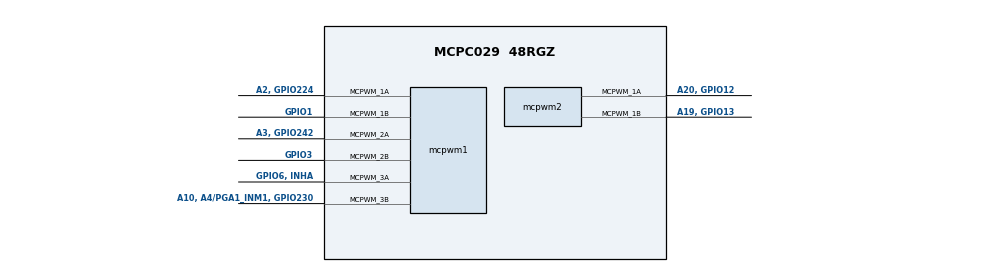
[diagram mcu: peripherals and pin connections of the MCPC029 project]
/**
 * @cliArgs --device "MCPC029" --part "MCPC029_48RGZ" --package "48RGZ"
 */
/**
 * Import the modules used in this configuration.
 */
const mcpwm  = scripting.addModule("/driverlib/mcpwm.js");
const mcpwm1 = mcpwm.addInstance();
const mcpwm2 = mcpwm.addInstance();
/**
 * Write custom configuration values to the imported modules.
 */
mcpwm.commentOutDefaultCode = true;
mcpwm1.$name                                                       = "myMCPWM0";
mcpwm1.mcpwmTimebase_counterMode                                   = "MCPWM_COUNTER_MODE_UP";
mcpwm1.mcpwmTimebase_period                                        = 15999;
mcpwm1.mcpwmCounterCompare_cmpA                                    = 7999;
mcpwm1.mcpwmTimebase_emulationMode                                 = "MCPWM_EMULATION_FREE_RUN";
mcpwm1.mcpwmCounterCompare_cmpB                                    = 7999;
mcpwm1.mcpwmActionQualifier_MCPWM_AQ_OUTPUT_1A_ON_TIMEBASE_ZERO    = "MCPWM_AQ_OUTPUT_HIGH";
mcpwm1.mcpwmActionQualifier_MCPWM_AQ_OUTPUT_1B_ON_TIMEBASE_ZERO    = "MCPWM_AQ_OUTPUT_HIGH";
mcpwm1.mcpwmActionQualifier_MCPWM_AQ_OUTPUT_1A_ON_TIMEBASE_UP_CMPA = "MCPWM_AQ_OUTPUT_LOW";
mcpwm1.mcpwmActionQualifier_MCPWM_AQ_OUTPUT_1B_ON_TIMEBASE_UP_CMPB = "MCPWM_AQ_OUTPUT_LOW";
mcpwm1.mcpwmActionQualifier_MCPWM_AQ_OUTPUT_2A_ON_TIMEBASE_PERIOD  = "MCPWM_AQ_OUTPUT_LOW";
mcpwm1.mcpwmActionQualifier_MCPWM_AQ_OUTPUT_2B_ON_TIMEBASE_PERIOD  = "MCPWM_AQ_OUTPUT_LOW";
mcpwm1.mcpwmActionQualifier_MCPWM_AQ_OUTPUT_2A_ON_TIMEBASE_UP_CMPA = "MCPWM_AQ_OUTPUT_HIGH";
mcpwm1.mcpwmActionQualifier_MCPWM_AQ_OUTPUT_2B_ON_TIMEBASE_UP_CMPB = "MCPWM_AQ_OUTPUT_HIGH";
mcpwm1.mcpwmActionQualifier_MCPWM_AQ_OUTPUT_3A_ON_TIMEBASE_UP_CMPA = "MCPWM_AQ_OUTPUT_HIGH";
mcpwm1.mcpwmActionQualifier_MCPWM_AQ_OUTPUT_3A_ON_TIMEBASE_UP_CMPB = "MCPWM_AQ_OUTPUT_LOW";
mcpwm1.mcpwmActionQualifier_MCPWM_AQ_OUTPUT_3B_ON_TIMEBASE_UP_CMPA = "MCPWM_AQ_OUTPUT_LOW";
mcpwm1.mcpwmActionQualifier_MCPWM_AQ_OUTPUT_3B_ON_TIMEBASE_UP_CMPB = "MCPWM_AQ_OUTPUT_HIGH";
mcpwm1.mcpwmEventTrigger_MCPWM_ET_1_triggerEnable                  = true;
mcpwm1.mcpwmEventTrigger_MCPWM_ET_1_triggerSource                  = "MCPWM_EVT_TBCTR_PERIOD";
mcpwm1.mcpwmEventTrigger_MCPWM_ET_1_triggerEventPrescalar          = "5";
mcpwm1.mcpwmEventTrigger_enableInterrupt                           = true;
mcpwm1.mcpwmEventTrigger_registerInterrupts                        = true;
mcpwm1.mcpwmEventTrigger_interruptSource                           = ["MCPWM_INT_ET_1"];
mcpwm1.mcpwmCounterCompare_cmpA_pwm2                               = 7999;
mcpwm1.mcpwmCounterCompare_cmpB_pwm2                               = 7999;
mcpwm1.mcpwmCounterCompare_cmpB_pwm3                               = 7999;
mcpwm1.mcpwmCounterCompare_cmpA_pwm3                               = 7999;
mcpwm1.mcpwm.$assign                                               = "MCPWM1";
mcpwm1.mcpwm.mcpwm_1aPin.$assign                                   = "A2, GPIO224";
mcpwm1.mcpwm.mcpwm_1bPin.$assign                                   = "GPIO1";
mcpwm1.mcpwm.mcpwm_2aPin.$assign                                   = "A3, GPIO242";
mcpwm1.mcpwm.mcpwm_2bPin.$assign                                   = "GPIO3";
mcpwm1.mcpwm.mcpwm_3aPin.$assign                                   = "GPIO6, INHA";
mcpwm1.mcpwm.mcpwm_3bPin.$assign                                   = "A10, A4/PGA1_INM1, GPIO230";
mcpwm1.mcpwmInt.enableInterrupt                                    = true;
mcpwm2.$name                                                         = "myMCPWM1";
mcpwm2.useCase                                                       = "2CH";
mcpwm2.mcpwmTimebase_emulationMode                                   = "MCPWM_EMULATION_FREE_RUN";
mcpwm2.mcpwmTimebase_counterMode                                     = "MCPWM_COUNTER_MODE_UP_DOWN";
mcpwm2.mcpwmTimebase_period                                          = 8000;
mcpwm2.mcpwmActionQualifier_MCPWM_AQ_OUTPUT_1A_ON_TIMEBASE_UP_CMPA   = "MCPWM_AQ_OUTPUT_HIGH";
mcpwm2.mcpwmActionQualifier_MCPWM_AQ_OUTPUT_1A_ON_TIMEBASE_DOWN_CMPA = "MCPWM_AQ_OUTPUT_LOW";
mcpwm2.mcpwmActionQualifier_MCPWM_AQ_OUTPUT_1B_ON_TIMEBASE_UP_CMPB   = "MCPWM_AQ_OUTPUT_HIGH";
mcpwm2.mcpwmActionQualifier_MCPWM_AQ_OUTPUT_1B_ON_TIMEBASE_DOWN_CMPB = "MCPWM_AQ_OUTPUT_LOW";
mcpwm2.mcpwmEventTrigger_enableInterrupt                             = true;
mcpwm2.mcpwmEventTrigger_registerInterrupts                          = true;
mcpwm2.mcpwmEventTrigger_interruptSource                             = ["MCPWM_INT_ET_1"];
mcpwm2.mcpwmEventTrigger_MCPWM_ET_1_triggerEnable                    = true;
mcpwm2.mcpwmEventTrigger_MCPWM_ET_1_triggerSource                    = "MCPWM_EVT_TBCTR_PERIOD";
mcpwm2.mcpwmEventTrigger_MCPWM_ET_1_triggerEventPrescalar            = "5";
mcpwm2.mcpwm.$assign                                                 = "MCPWM3";
mcpwm2.mcpwm.mcpwm_1aPin.$assign                                     = "A20, GPIO12";
mcpwm2.mcpwm.mcpwm_1bPin.$assign                                     = "A19, GPIO13";
mcpwm2.mcpwmInt.enableInterrupt                                      = true;
